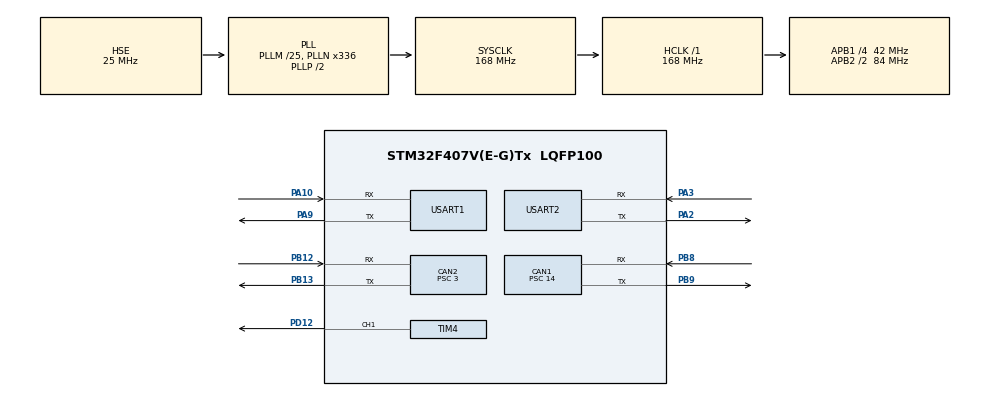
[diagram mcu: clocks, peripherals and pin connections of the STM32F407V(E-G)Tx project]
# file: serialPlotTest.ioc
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CAN1.ABOM=ENABLE
CAN1.BS1=CAN_BS1_4TQ
CAN1.BS2=CAN_BS2_1TQ
CAN1.SJW=CAN_SJW_1TQ
CAN1.CalculateBaudRate=500000
CAN1.CalculateTimeBit=2000
CAN1.CalculateTimeQuantum=333.33333333333337
CAN1.NART=ENABLE
CAN1.Prescaler=14
CAN2.ABOM=ENABLE
CAN2.BS1=CAN_BS1_11TQ
CAN2.BS2=CAN_BS2_2TQ
CAN2.CalculateBaudRate=1000000
CAN2.CalculateTimeBit=1000
CAN2.CalculateTimeQuantum=71.42857142857143
CAN2.NART=ENABLE
CAN2.Prescaler=3
Dma.Request0=USART1_TX
Dma.USART1_TX.0.Direction=DMA_MEMORY_TO_PERIPH
Dma.USART1_TX.0.FIFOMode=DMA_FIFOMODE_DISABLE
Dma.USART1_TX.0.Instance=DMA2_Stream7
Dma.USART1_TX.0.MemDataAlignment=DMA_MDATAALIGN_BYTE
Dma.USART1_TX.0.MemInc=DMA_MINC_ENABLE
Dma.USART1_TX.0.Mode=DMA_NORMAL
Dma.USART1_TX.0.PeriphDataAlignment=DMA_PDATAALIGN_BYTE
Dma.USART1_TX.0.PeriphInc=DMA_PINC_DISABLE
Dma.USART1_TX.0.Priority=DMA_PRIORITY_MEDIUM
Mcu.Family=STM32F4
Mcu.Name=STM32F407V(E-G)Tx
Mcu.Package=LQFP100
NVIC.CAN1_TX_IRQn=true\:3\:0\:true\:false\:true\:true\:true\:true
NVIC.CAN1_SCE_IRQn=true\:3\:0\:true\:false\:true\:true\:true\:true
NVIC.CAN1_RX0_IRQn=true\:3\:0\:true\:false\:true\:true\:true\:true
NVIC.CAN2_RX0_IRQn=true\:3\:0\:true\:false\:true\:true\:true\:true
NVIC.DMA2_Stream7_IRQn=true\:5\:0\:false\:false\:true\:false\:true\:true
NVIC.PriorityGroup=NVIC_PRIORITYGROUP_4
NVIC.TIM3_IRQn=true\:4\:0\:true\:false\:true\:true\:true\:true
NVIC.USART1_IRQn=true\:2\:0\:true\:false\:true\:true\:true\:true
NVIC.USART2_IRQn=true\:1\:0\:true\:false\:true\:true\:true\:true
PA10.Mode=Asynchronous
PA10.Signal=USART1_RX
PA13.Mode=Serial_Wire
PA13.Signal=SYS_JTMS-SWDIO
PA14.Mode=Serial_Wire
PA14.Signal=SYS_JTCK-SWCLK
PA2.Mode=Asynchronous
PA2.Signal=USART2_TX
PA3.Mode=Asynchronous
PA3.Signal=USART2_RX
PA9.Mode=Asynchronous
PA9.Signal=USART1_TX
PB12.Mode=CAN_Activate
PB12.Signal=CAN2_RX
PB13.Mode=CAN_Activate
PB13.Signal=CAN2_TX
PB8.Mode=CAN_Activate
PB8.Signal=CAN1_RX
PB9.Mode=CAN_Activate
PB9.Signal=CAN1_TX
PD12.Signal=S_TIM4_CH1
PH0-OSC_IN.Mode=HSE-External-Oscillator
PH0-OSC_IN.Signal=RCC_OSC_IN
PH1-OSC_OUT.Mode=HSE-External-Oscillator
PH1-OSC_OUT.Signal=RCC_OSC_OUT
ProjectManager.HeapSize=0x800
ProjectManager.StackSize=0x800
ProjectManager.TargetToolchain=STM32CubeIDE
RCC.48MHZClocksFreq_Value=84000000
RCC.AHBFreq_Value=168000000
RCC.APB1CLKDivider=RCC_HCLK_DIV4
RCC.APB1Freq_Value=42000000
RCC.APB1TimFreq_Value=84000000
RCC.APB2CLKDivider=RCC_HCLK_DIV2
RCC.APB2Freq_Value=84000000
RCC.APB2TimFreq_Value=168000000
RCC.CortexFreq_Value=168000000
RCC.HCLKFreq_Value=168000000
RCC.HSE_VALUE=25000000
RCC.HSI_VALUE=16000000
RCC.LSE_VALUE=32768
RCC.PLLM=25
RCC.PLLN=336
RCC.PLLSourceVirtual=RCC_PLLSOURCE_HSE
RCC.SYSCLKFreq_VALUE=168000000
RCC.SYSCLKSource=RCC_SYSCLKSOURCE_PLLCLK
RCC.VCOOutputFreq_Value=336000000
SH.S_TIM4_CH1.0=TIM4_CH1,PWM Generation1 CH1
TIM3.Period=100-1
TIM3.Prescaler=8400-1
TIM4.Channel-PWM\ Generation1\ CH1=TIM_CHANNEL_1
TIM4.Period=20000-1
TIM4.Prescaler=84-1
USART1.VirtualMode=VM_ASYNC
USART2.VirtualMode=VM_ASYNC
VP_TIM3_VS_ClockSourceINT.Mode=Internal
VP_TIM4_VS_ClockSourceINT.Mode=Internal
board=custom

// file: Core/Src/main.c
/* USER CODE BEGIN Header */
/**
  ******************************************************************************
  * @file           : main.c
  * @brief          : Main program body
  ******************************************************************************
  * @attention
  *
  * Copyright (c) 2026 STMicroelectronics.
  * All rights reserved.
  *
  * This software is licensed under terms that can be found in the LICENSE file
  * in the root directory of this software component.
  * If no LICENSE file comes with this software, it is provided AS-IS.
  *
  ******************************************************************************
  */
/* USER CODE END Header */
#include "main.h"
#include "can.h"
#include "dma.h"
#include "tim.h"
#include "usart.h"
#include "gpio.h"

/* USER CODE BEGIN Includes */
#include "robot_app.h"
/* USER CODE END Includes */

void SystemClock_Config(void);

int main(void)
{

  /* MCU Configuration--------------------------------------------------------*/

  /* Reset of all peripherals, Initializes the Flash interface and the Systick. */
  HAL_Init();

  /* Configure the system clock */
  SystemClock_Config();

  /* Initialize all configured peripherals */
  MX_GPIO_Init();
  MX_DMA_Init();
  MX_CAN1_Init();
  MX_USART1_UART_Init();
  MX_TIM3_Init();
  MX_USART2_UART_Init();
  MX_TIM4_Init();
  MX_CAN2_Init();
  /* USER CODE BEGIN 2 */
  RobotApp_Init();
  /* USER CODE END 2 */

  /* Infinite loop */
  while (1)
  {

    /* USER CODE BEGIN 3 */
      RobotApp_Process();
  }
  /* USER CODE END 3 */
}

void SystemClock_Config(void)
{
  RCC_OscInitTypeDef RCC_OscInitStruct = {0};
  RCC_ClkInitTypeDef RCC_ClkInitStruct = {0};

  /** Configure the main internal regulator output voltage
  */
  __HAL_RCC_PWR_CLK_ENABLE();
  __HAL_PWR_VOLTAGESCALING_CONFIG(PWR_REGULATOR_VOLTAGE_SCALE1);

  /** Initializes the RCC Oscillators according to the specified parameters
  * in the RCC_OscInitTypeDef structure.
  */
  RCC_OscInitStruct.OscillatorType = RCC_OSCILLATORTYPE_HSE;
  RCC_OscInitStruct.HSEState = RCC_HSE_ON;
  RCC_OscInitStruct.PLL.PLLState = RCC_PLL_ON;
  RCC_OscInitStruct.PLL.PLLSource = RCC_PLLSOURCE_HSE;
  RCC_OscInitStruct.PLL.PLLM = 25;
  RCC_OscInitStruct.PLL.PLLN = 336;
  RCC_OscInitStruct.PLL.PLLP = RCC_PLLP_DIV2;
  RCC_OscInitStruct.PLL.PLLQ = 4;
  if (HAL_RCC_OscConfig(&RCC_OscInitStruct) != HAL_OK)
  {
    Error_Handler();
  }

  /** Initializes the CPU, AHB and APB buses clocks
  */
  RCC_ClkInitStruct.ClockType = RCC_CLOCKTYPE_HCLK|RCC_CLOCKTYPE_SYSCLK
                              |RCC_CLOCKTYPE_PCLK1|RCC_CLOCKTYPE_PCLK2;
  RCC_ClkInitStruct.SYSCLKSource = RCC_SYSCLKSOURCE_PLLCLK;
  RCC_ClkInitStruct.AHBCLKDivider = RCC_SYSCLK_DIV1;
  RCC_ClkInitStruct.APB1CLKDivider = RCC_HCLK_DIV4;
  RCC_ClkInitStruct.APB2CLKDivider = RCC_HCLK_DIV2;

  if (HAL_RCC_ClockConfig(&RCC_ClkInitStruct, FLASH_LATENCY_5) != HAL_OK)
  {
    Error_Handler();
  }
}

void Error_Handler(void)
{
  __disable_irq();
  while (1)
  {
  }
}
